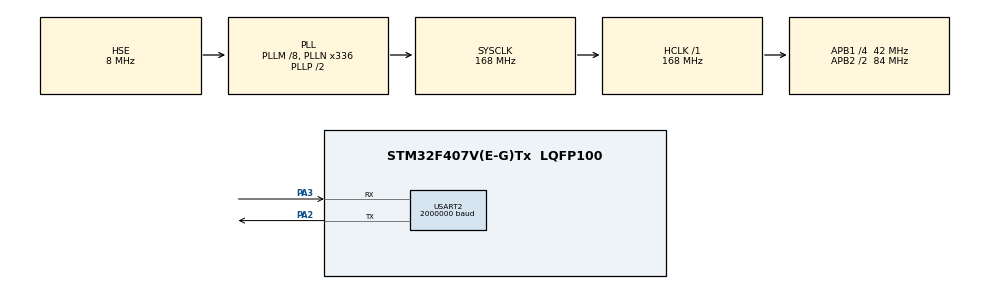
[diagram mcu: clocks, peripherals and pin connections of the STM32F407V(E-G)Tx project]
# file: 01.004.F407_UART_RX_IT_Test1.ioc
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Mcu.Family=STM32F4
Mcu.Name=STM32F407V(E-G)Tx
Mcu.Package=LQFP100
NVIC.PriorityGroup=NVIC_PRIORITYGROUP_0
NVIC.USART2_IRQn=true\:0\:0\:false\:false\:true\:true\:true\:true
PA2.Mode=Asynchronous
PA2.Signal=USART2_TX
PA3.Mode=Asynchronous
PA3.Signal=USART2_RX
PH0-OSC_IN.Mode=HSE-External-Oscillator
PH0-OSC_IN.Signal=RCC_OSC_IN
PH1-OSC_OUT.Mode=HSE-External-Oscillator
PH1-OSC_OUT.Signal=RCC_OSC_OUT
ProjectManager.HeapSize=0x200
ProjectManager.StackSize=0x400
ProjectManager.TargetToolchain=STM32CubeIDE
RCC.48MHZClocksFreq_Value=48000000
RCC.AHBFreq_Value=168000000
RCC.APB1CLKDivider=RCC_HCLK_DIV4
RCC.APB1Freq_Value=42000000
RCC.APB1TimFreq_Value=84000000
RCC.APB2CLKDivider=RCC_HCLK_DIV2
RCC.APB2Freq_Value=84000000
RCC.APB2TimFreq_Value=168000000
RCC.CortexFreq_Value=168000000
RCC.HCLKFreq_Value=168000000
RCC.HSE_VALUE=8000000
RCC.HSI_VALUE=16000000
RCC.LSE_VALUE=32768
RCC.PLLM=8
RCC.PLLN=336
RCC.PLLQ=7
RCC.PLLSourceVirtual=RCC_PLLSOURCE_HSE
RCC.SYSCLKFreq_VALUE=168000000
RCC.SYSCLKSource=RCC_SYSCLKSOURCE_PLLCLK
RCC.VCOOutputFreq_Value=336000000
USART2.BaudRate=2000000
USART2.VirtualMode=VM_ASYNC
board=STM32F407G-DISC1

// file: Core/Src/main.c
/* USER CODE BEGIN Header */
/**
  ******************************************************************************
  * @file           : main.c
  * @brief          : Main program body
  ******************************************************************************
  * @attention
  *
  * Copyright (c) 2025 STMicroelectronics.
  * All rights reserved.
  *
  * This software is licensed under terms that can be found in the LICENSE file
  * in the root directory of this software component.
  * If no LICENSE file comes with this software, it is provided AS-IS.
  *
  ******************************************************************************
  */
/* USER CODE END Header */
#include "main.h"

/* USER CODE BEGIN Includes */
/*
 * HAL_UART_Receive_IT(&huart2, &rx_data, 1); was important that placed inside
 * simple_uart_init();
 * Both WaveShare and Mikroe USB UART Click is tested at 2M baud rate(TeraTerm)
 * */

#include <stdio.h>
#include <string.h>
#include <stddef.h>
#include <stdarg.h>
#include <stdbool.h>
#include <stdlib.h>
/* USER CODE END Includes */

UART_HandleTypeDef huart4;

/* USER CODE BEGIN PV */
// Simple variables
uint8_t rx_data = 0;               // Single byte received
volatile uint8_t rx_flag = 0;      // New data flag
uint8_t rx_count = 0;              // Count received bytes
/* USER CODE END PV */

void SystemClock_Config(void);
static void MX_GPIO_Init(void);
static void MX_USART2_UART_Init(void);

/* USER CODE BEGIN 0 */

void DebugPrint(const char *format, ...)
{
    char uartBuffer[250];
    va_list args;
    va_start(args, format);

    vsnprintf(uartBuffer, sizeof(uartBuffer), format, args);
    va_end(args);

    HAL_UART_Transmit(&huart4, (uint8_t*)uartBuffer, strlen(uartBuffer), HAL_MAX_DELAY);
}

void simple_uart_init(void)
{
    // Start UART reception interrupt
    if (HAL_UART_Receive_IT(&huart4, &rx_data, 1) != HAL_OK) {
    	DebugPrint("ERROR: Could not start UART RX interrupt!\r\n");
    } else {
    	DebugPrint("UART RX interrupt started successfully!\r\n");
    }

    // Print simple instructions
    DebugPrint("\r\n");
    DebugPrint("=== SIMPLE UART RX IT TEST ===\r\n");
    DebugPrint("Type anything in terminal:\r\n");
    DebugPrint("- Characters will echo back\r\n");
    DebugPrint("- System will report what you typed\r\n");
    DebugPrint("- Try: a, 1, Enter, Space\r\n");
    DebugPrint("============================\r\n\r\n");
}

void simple_uart_test(void)
{
    if (rx_flag == 1)  // New data received?
    {
        // Print what we received
    	DebugPrint("RX: 0x%02X ('%c') - Count: %d\r\n", rx_data, rx_data, rx_count);

        // Test different characters
        switch (rx_data)
        {
            case 'a':
            case 'A':
            	DebugPrint("You pressed 'A'!\r\n");
                break;

            case '1':
            	DebugPrint("Number 1 detected!\r\n");
                break;

            case '\r':  // Enter key
            case '\n':
            	DebugPrint("Enter key pressed!\r\n");
                break;

            case ' ':   // Space
            	DebugPrint("Space bar pressed!\r\n");
                break;

            default:
            	DebugPrint("Other character received\r\n");
                break;
        }
        DebugPrint("\r\n");
        // Clear the flag
        rx_flag = 0;
    }
}

/* USER CODE END 0 */

int main(void)
{

  /* MCU Configuration--------------------------------------------------------*/

  /* Reset of all peripherals, Initializes the Flash interface and the Systick. */
  HAL_Init();

  /* Configure the system clock */
  SystemClock_Config();

  /* Initialize all configured peripherals */
  MX_GPIO_Init();
  MX_USART2_UART_Init();
  /* USER CODE BEGIN 2 */
  simple_uart_init();
  /* USER CODE END 2 */

  /* Infinite loop */
  while (1)
  {

    /* USER CODE BEGIN 3 */
	  /* Test UART reception */
	  simple_uart_test();

	  /* Small delay */
	  HAL_Delay(10);

  }
  /* USER CODE END 3 */
}

void SystemClock_Config(void)
{
  RCC_OscInitTypeDef RCC_OscInitStruct = {0};
  RCC_ClkInitTypeDef RCC_ClkInitStruct = {0};

  /** Configure the main internal regulator output voltage
  */
  __HAL_RCC_PWR_CLK_ENABLE();
  __HAL_PWR_VOLTAGESCALING_CONFIG(PWR_REGULATOR_VOLTAGE_SCALE1);

  /** Initializes the RCC Oscillators according to the specified parameters
  * in the RCC_OscInitTypeDef structure.
  */
  RCC_OscInitStruct.OscillatorType = RCC_OSCILLATORTYPE_HSE;
  RCC_OscInitStruct.HSEState = RCC_HSE_ON;
  RCC_OscInitStruct.PLL.PLLState = RCC_PLL_ON;
  RCC_OscInitStruct.PLL.PLLSource = RCC_PLLSOURCE_HSE;
  RCC_OscInitStruct.PLL.PLLM = 8;
  RCC_OscInitStruct.PLL.PLLN = 336;
  RCC_OscInitStruct.PLL.PLLP = RCC_PLLP_DIV2;
  RCC_OscInitStruct.PLL.PLLQ = 7;
  if (HAL_RCC_OscConfig(&RCC_OscInitStruct) != HAL_OK)
  {
    Error_Handler();
  }

  /** Initializes the CPU, AHB and APB buses clocks
  */
  RCC_ClkInitStruct.ClockType = RCC_CLOCKTYPE_HCLK|RCC_CLOCKTYPE_SYSCLK
                              |RCC_CLOCKTYPE_PCLK1|RCC_CLOCKTYPE_PCLK2;
  RCC_ClkInitStruct.SYSCLKSource = RCC_SYSCLKSOURCE_PLLCLK;
  RCC_ClkInitStruct.AHBCLKDivider = RCC_SYSCLK_DIV1;
  RCC_ClkInitStruct.APB1CLKDivider = RCC_HCLK_DIV4;
  RCC_ClkInitStruct.APB2CLKDivider = RCC_HCLK_DIV2;

  if (HAL_RCC_ClockConfig(&RCC_ClkInitStruct, FLASH_LATENCY_5) != HAL_OK)
  {
    Error_Handler();
  }
}

static void MX_USART2_UART_Init(void)
{

  huart4.Instance = USART2;
  huart4.Init.BaudRate = 2000000;
  huart4.Init.WordLength = UART_WORDLENGTH_8B;
  huart4.Init.StopBits = UART_STOPBITS_1;
  huart4.Init.Parity = UART_PARITY_NONE;
  huart4.Init.Mode = UART_MODE_TX_RX;
  huart4.Init.HwFlowCtl = UART_HWCONTROL_NONE;
  huart4.Init.OverSampling = UART_OVERSAMPLING_16;
  if (HAL_UART_Init(&huart4) != HAL_OK)
  {
    Error_Handler();
  }

}

static void MX_GPIO_Init(void)
{

  /* GPIO Ports Clock Enable */
  __HAL_RCC_GPIOH_CLK_ENABLE();
  __HAL_RCC_GPIOA_CLK_ENABLE();

}

/* USER CODE BEGIN 4 */
void HAL_UART_RxCpltCallback(UART_HandleTypeDef *huart)
{

	if (huart->Instance == USART2)
	    {
	        // Restart UART reception for next byte
	        if (HAL_UART_Receive_IT(&huart4, &rx_data, 1) != HAL_OK) {
	            DebugPrint("UART IT restart failed\r\n");
	        }

	        // Set flag that new data arrived
	        rx_flag = 1;

	        // Count received bytes
	        rx_count++;

	        // Echo the character back to terminal (so you can see what you typed)
	        DebugPrint("\r\nUART Rx Data: %d\r\n",rx_data);
	    }
}
/* USER CODE END 4 */

void Error_Handler(void)
{
  __disable_irq();
  while (1)
  {
  }
}
